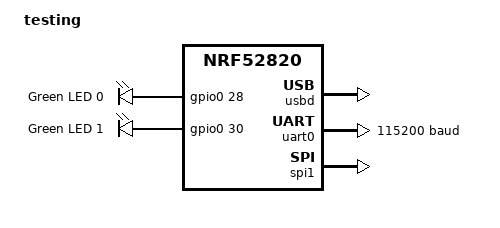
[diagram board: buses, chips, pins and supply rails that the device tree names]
/dts-v1/;
#include <nordic/nrf52820_qdaa.dtsi>
#include "TST-pinctrl.dtsi"

/ {
	model = "testing";
	compatible = "BY,TST";

	chosen {
		zephyr,sram = &sram0;
		zephyr,flash = &flash0;
		zephyr,code-partition = &slot0_partition;
		zephyr,console = &cdc_acm_uart0;
		zephyr,shell-uart = &cdc_acm_uart0;
		zephyr,uart-mcumgr = &cdc_acm_uart0;
	};

	leds {
		compatible = "gpio-leds";
		led0: led_0 {
			gpios = <&gpio0 28 GPIO_ACTIVE_HIGH>;
			label = "Green LED 0";
		};
		led1: led_1 {
			gpios = <&gpio0 30 GPIO_ACTIVE_HIGH>;
			label = "Green LED 1";
		};
	};

	aliases {
        led0 = &led0;
        led1 = &led1;
    };
};

&flash0 {
	partitions {
		compatible = "fixed-partitions";
		#address-cells = <1>;
		#size-cells = <1>;

		boot_partition: partition@0 {
			label = "mcuboot";
			reg = <0x00000000 DT_SIZE_K(48)>;
		};

		slot0_partition: partition@c000 {
			label = "image-0";
			reg = <0x0000c000 DT_SIZE_K(92)>;
		};

		slot1_partition: partition@23000 {
			label = "image-1";
			reg = <0x00023000 DT_SIZE_K(92)>;
		};

		storage_partition: partition@3a000 {
			label = "storage";
			reg = <0x0003a000 DT_SIZE_K(24)>;
		};
	};
};

&gpiote {
	status = "okay";
};

&gpio0 {
	status = "okay";
};
&clock {

	status = "okay";

};


zephyr_udc0: &usbd {
	compatible = "nordic,nrf-usbd";
	status = "okay";
};

&usbd {
    cdc_acm_uart0: cdc_acm_uart0 {
        compatible = "zephyr,cdc-acm-uart";
        label = "CDC_ACM_0";
    };
};

&uart0 {
 compatible = "nordic,nrf-uarte";
 status = "okay";
 current-speed = <115200>;
 pinctrl-0 = <&uart0_default>;
 pinctrl-1 = <&uart0_sleep>;
 pinctrl-names = "default", "sleep";
};

&spi1 {
 compatible = "nordic,nrf-spi";
 status = "okay";
 pinctrl-0 = <&spi1_default>;
 pinctrl-1 = <&spi1_sleep>;
 pinctrl-names = "default", "sleep";
};

